# STM32F401xC register map
File version: 1.0
Registers are 32-bit, read-write, reset 0x0 unless marked. A register's access mark holds for its fields unless they carry their own. Offsets are from the block's base; [hi:lo] are bit positions; {n}, {i} and the like mark numbered series.

## SDIO — SD host Interface
Base 0x40012C00
0x00 POWER — SDIO power control register
  [1:0] PWRCTRL — PWRCTRL[1:0] bits (Power supply control bits)
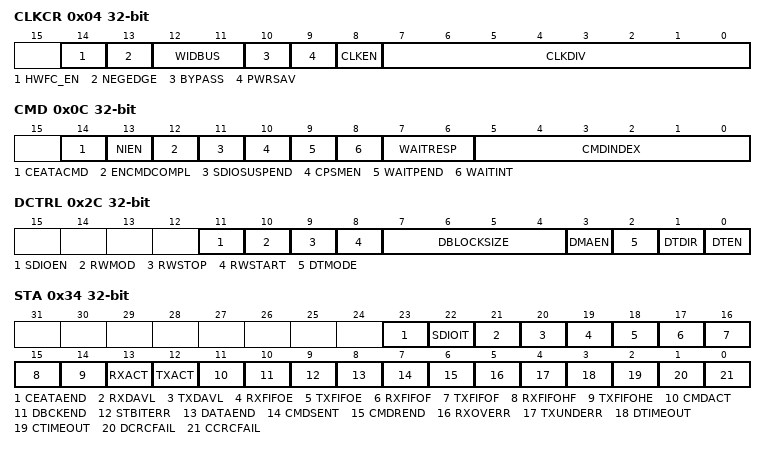
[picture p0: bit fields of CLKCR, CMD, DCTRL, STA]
0x04 CLKCR — SDI clock control register
  [14] HWFC_EN — HW Flow Control enable
  [13] NEGEDGE — SDIO_CK dephasing selection bit
  [12:11] WIDBUS — WIDBUS[1:0] bits (Wide bus mode enable bit)
  [10] BYPASS — Clock divider bypass enable bit
  [9] PWRSAV — Power saving configuration bit
  [8] CLKEN — Clock enable bit
  [7:0] CLKDIV — Clock divide factor
0x08 ARG — SDIO argument register
  [31:0] CMDARG — Command argument
0x0C CMD — SDIO command register
  [14] CEATACMD — CE-ATA command
  [13] NIEN — Not Interrupt Enable
  [12] ENCMDCOMPL — Enable CMD completion
  [11] SDIOSUSPEND — SD I/O suspend command
  [10] CPSMEN — Command path state machine (CPSM) Enable bit
  [9] WAITPEND — CPSM Waits for ends of data transfer (CmdPend internal signal)
  [8] WAITINT — CPSM Waits for Interrupt Request
  [7:6] WAITRESP — WAITRESP[1:0] bits (Wait for response bits)
  [5:0] CMDINDEX — Command Index
0x10 RESPCMD ro — SDIO command response register
  [5:0] RESPCMD — Response command index
{0x10+4i} RESP{i} ro (i=1..4) — SDIO response {i} register
  [31:0] CARDSTATUS{i} — Card Status
0x24 DTIMER — SDIO data timer register
  [31:0] DATATIME — Data timeout period
0x28 DLEN — SDIO data length register
  [24:0] DATALENGTH — Data length value
0x2C DCTRL — SDIO data control register
  [11] SDIOEN — SD I/O enable functions
  [10] RWMOD — Read wait mode
  [9] RWSTOP — Read wait stop
  [8] RWSTART — Read wait start
  [7:4] DBLOCKSIZE — DBLOCKSIZE[3:0] bits (Data block size)
  [3] DMAEN — DMA enabled bit
  [2] DTMODE — Data transfer mode selection
  [1] DTDIR — Data transfer direction selection
  [0] DTEN — Data transfer enabled bit
0x30 DCOUNT ro — SDIO data counter register
  [24:0] DATACOUNT — Data count value
0x34 STA ro — SDIO status register
  [23] CEATAEND — CE-ATA command completion signal received for CMD61
  [22] SDIOIT — SDIO interrupt received
  [21] RXDAVL — Data available in receive FIFO
  [20] TXDAVL — Data available in transmit FIFO
  [19] RXFIFOE — Receive FIFO empty
  [18] TXFIFOE — Transmit FIFO empty
  [17] RXFIFOF — Receive FIFO full
  [16] TXFIFOF — Transmit FIFO full
  [15] RXFIFOHF — Receive FIFO Half Full: there are at least 8 words in the FIFO
  [14] TXFIFOHE — Transmit FIFO Half Empty: at least 8 words can be written into the FIFO
  [13] RXACT — Data receive in progress
  [12] TXACT — Data transmit in progress
  [11] CMDACT — Command transfer in progress
  [10] DBCKEND — Data block sent/received (CRC check passed)
  [9] STBITERR — Start bit not detected on all data signals in wide bus mode
  [8] DATAEND — Data end (data counter, SDIDCOUNT, is zero)
  [7] CMDSENT — Command sent (no response required)
  [6] CMDREND — Command response received (CRC check passed)
  [5] RXOVERR — Received FIFO overrun error
  [4] TXUNDERR — Transmit FIFO underrun error
  [3] DTIMEOUT — Data timeout
  [2] CTIMEOUT — Command response timeout
  [1] DCRCFAIL — Data block sent/received (CRC check failed)
  [0] CCRCFAIL — Command response received (CRC check failed)
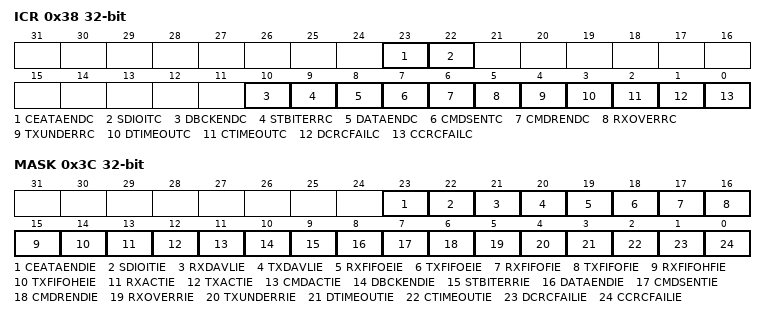
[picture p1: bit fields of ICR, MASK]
0x38 ICR — SDIO interrupt clear register
  [23] CEATAENDC — CEATAEND flag clear bit
  [22] SDIOITC — SDIOIT flag clear bit
  [10] DBCKENDC — DBCKEND flag clear bit
  [9] STBITERRC — STBITERR flag clear bit
  [8] DATAENDC — DATAEND flag clear bit
  [7] CMDSENTC — CMDSENT flag clear bit
  [6] CMDRENDC — CMDREND flag clear bit
  [5] RXOVERRC — RXOVERR flag clear bit
  [4] TXUNDERRC — TXUNDERR flag clear bit
  [3] DTIMEOUTC — DTIMEOUT flag clear bit
  [2] CTIMEOUTC — CTIMEOUT flag clear bit
  [1] DCRCFAILC — DCRCFAIL flag clear bit
  [0] CCRCFAILC — CCRCFAIL flag clear bit
0x3C MASK — SDIO mask register
  [23] CEATAENDIE — CE-ATA command completion signal received Interrupt Enable
  [22] SDIOITIE — SDIO Mode Interrupt Received interrupt Enable
  [21] RXDAVLIE — Data available in Rx FIFO interrupt Enable
  [20] TXDAVLIE — Data available in Tx FIFO interrupt Enable
  [19] RXFIFOEIE — Rx FIFO Empty interrupt Enable
  [18] TXFIFOEIE — Tx FIFO Empty interrupt Enable
  [17] RXFIFOFIE — Rx FIFO Full interrupt Enable
  [16] TXFIFOFIE — Tx FIFO Full interrupt Enable
  [15] RXFIFOHFIE — Rx FIFO Half Full interrupt Enable
  [14] TXFIFOHEIE — Tx FIFO Half Empty interrupt Enable
  [13] RXACTIE — Data receive acting interrupt enabled
  [12] TXACTIE — Data Transmit Acting Interrupt Enable
  [11] CMDACTIE — CCommand Acting Interrupt Enable
  [10] DBCKENDIE — Data Block End Interrupt Enable
  [9] STBITERRIE — Start Bit Error Interrupt Enable
  [8] DATAENDIE — Data End Interrupt Enable
  [7] CMDSENTIE — Command Sent Interrupt Enable
  [6] CMDRENDIE — Command Response Received Interrupt Enable
  [5] RXOVERRIE — Rx FIFO OverRun Error Interrupt Enable
  [4] TXUNDERRIE — Tx FIFO UnderRun Error Interrupt Enable
  [3] DTIMEOUTIE — Data TimeOut Interrupt Enable
  [2] CTIMEOUTIE — Command TimeOut Interrupt Enable
  [1] DCRCFAILIE — Data CRC Fail Interrupt Enable
  [0] CCRCFAILIE — Command CRC Fail Interrupt Enable
0x48 FIFOCNT ro — SDIO FIFO counter register
  [23:0] FIFOCOUNT — Remaining number of words to be written to or read from the FIFO
0x80 FIFO — SDIO data FIFO register
  [31:0] FIFODATA — Receive and transmit FIFO data
